# RT584ZCM33 register map
Series: ARMv8-M Mainline; File version: 1.0
CPU: CM33 r0p0, little endian, MPU, no FPU, VTOR, 3 interrupt priority bits
Registers are 32-bit, read-write, reset 0x0 unless marked. A register's access mark holds for its fields unless they carry their own. Offsets are from the block's base; [hi:lo] are bit positions.

## IRM_Non-Secure — IRM Non-Secure Register block
Base 0x40024000
Same registers: IRM_Secure 0x50024000
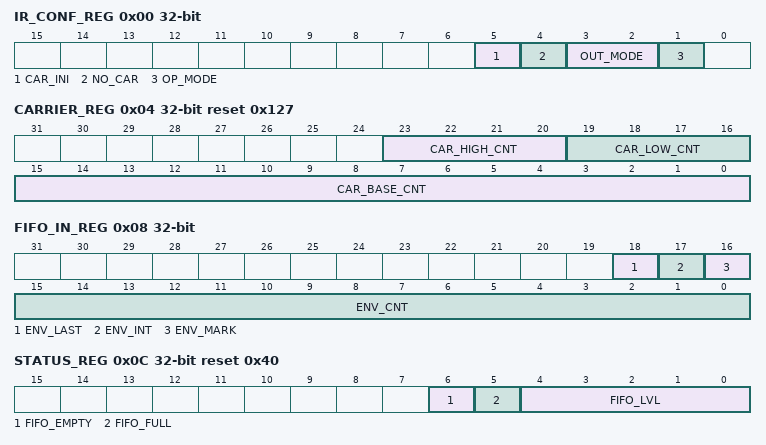
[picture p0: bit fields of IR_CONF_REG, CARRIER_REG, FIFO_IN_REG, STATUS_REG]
0x00 IR_CONF_REG — ir conf
  [5] CAR_INI — Initial Carrier Value 0: Carrier starts with '0' (the carrier is low during CAR_LOW_CNT and high during CAR_HIGH_CNT) 1: Carrier starts with '1' (the carrier is high during CAR_LOW_CNT and low during CAR_HIGH_CNT)
    0=B_5_ITEM0 (Carrier starts with '0' (the carrier is low during CAR_LOW_CNT and high during CAR_HIGH_CNT)); 1=B_5_ITEM1 (Carrier starts with '1' (the carrier is high during CAR_LOW_CNT and low during CAR_HIGH_CNT))
  [4] NO_CAR — No Carrier 0: Normal. IR Modulator output = envelope + carrier 1: Carrier is inhibited. IR Modulator output = envelope only
    0=B_4_ITEM0 (Normal. IR Modulator output = envelope + carrier); 1=B_4_ITEM1 (Carrier is inhibited. IR Modulator output = envelope only)
  [3:2] OUT_MODE — Output Logic Function 0: envelope AND carrier 1: envelope OR carrier 2: envelope NAND carrier 3: envelope NOR carrier
    0=B_2_to_3_ITEM0 (envelope AND carrier); 1=B_2_to_3_ITEM1 (envelope OR carrier); 2=B_2_to_3_ITEM2 (envelope NAND carrier); 3=B_2_to_3_ITEM3 (envelope NOR carrier)
  [1] OP_MODE — Operation mode 0: Normal Mode. IR Modulator will stop when it encounters an envelope with FIFO_IN[ENV_LAST]= 1. 1: Auto Mode. IR Modulator will transmit all envelopes and stop only when FIFO becomes empty. FIFO_IN[ENV_LAST] bit only generates an interrupt but doesn't stop.
    0=B_1_ITEM0 (Normal Mode. IR Modulator will stop when it encounters an envelope with FIFO_IN[ENV_LAST]= 1.); 1=B_1_ITEM1 (Auto Mode. IR Modulator will transmit all envelopes and stop only when FIFO becomes empty. FIFO_IN[ENV_LAST] bit only generates an interrupt but doesn't stop.)
0x04 CARRIER_REG reset 0x127 — carrier
  [23:20] CAR_HIGH_CNT — Carrier high level duration = (CAR_HIGH_CNT + 1) * CAR_BASE_CNT.
    0=B_20_to_23 (Carrier high level duration = (CAR_HIGH_CNT + 1) * CAR_BASE_CNT.)
  [19:16] CAR_LOW_CNT — Carrier low level duration = (CAR_LOW_CNT + 1) * CAR_BASE_CNT.
    0=B_16_to_19 (Carrier low level duration = (CAR_LOW_CNT + 1) * CAR_BASE_CNT.)
  [15:0] CAR_BASE_CNT — The divisor for target carrier frequency from IR source clock (32 MHz). Value 0x0 is equivalent to 0x1.
0x08 FIFO_IN_REG — fifo in
  [18] ENV_LAST wo — Last Envelope 0: IR Modulator loads the next envelope when this envelope finishes. 1: IR Modulator stops and generates an interrupt when this envelope is completely transmitted. If IR_CONF[OP_MODE] = 1, IR Modulator only generates an interrupt.
    0=B_18_ITEM0 (IR Modulator loads the next envelope when this envelope finishes.); 1=B_18_ITEM1 (IR Modulator stops and generates an interrupt when this envelope is completely transmitted. If IR_CONF[OP_MODE] = 1, IR Modulator only generates an interrupt.)
  [17] ENV_INT wo — Envelope Interrupt Generate an interrupt when starting emission of the envelope. 0: Not generate interrupt 1: Generate interrupt
    0=B_17_ITEM0 (Not generate interrupt); 1=B_17_ITEM1 (Generate interrupt)
  [16] ENV_MARK wo — Envelope Mark 0: the envelope period is a space 1: the envelope period is a mark
    0=B_16_ITEM0 (the envelope period is a space); 1=B_16_ITEM1 (the envelope period is a mark)
  [15:0] ENV_CNT wo — Envelope Duration Envelope duration expressed in carrier period number. Value 0x0000 has the same behavior as the value 0x0001.
0x0C STATUS_REG ro reset 0x40 — status
  [6] FIFO_EMPTY — IR Modulator FIFO Empty Flag 0: FIFO is not empty 1: FIFO is empty (FIFO level = 000000)
    0=B_6_ITEM0 (FIFO is not empty); 1=B_6_ITEM1 (FIFO is empty (FIFO level = 000000))
  [5] FIFO_FULL — IR Modulator FIFO Full Flag 0: FIFO is not full 1: FIFO is full (FIFO level = 100000)
    0=B_5_ITEM0 (FIFO is not full); 1=B_5_ITEM1 (FIFO is full (FIFO level = 100000))
  [4:0] FIFO_LVL — Current IR Modulator FIFO Level 0: Empty 1: 1 entry 16: 16 entries (FIFO is full)
    0=B_0_to_4 (Current IR Modulator FIFO Level 0: Empty 1: 1 entry 16: 16 entries (FIFO is full))
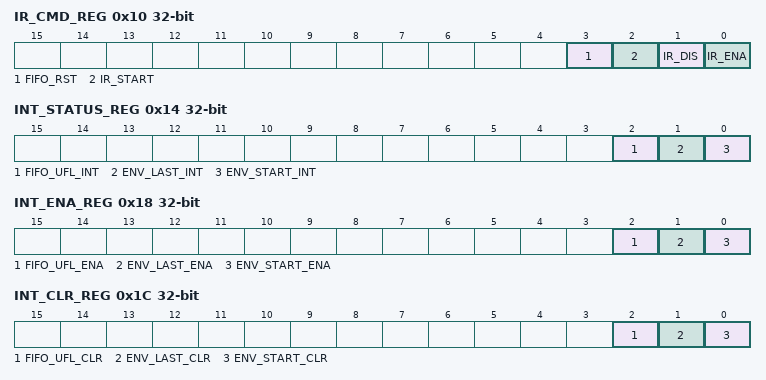
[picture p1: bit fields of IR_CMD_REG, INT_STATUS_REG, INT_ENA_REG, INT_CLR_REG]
0x10 IR_CMD_REG — ir cmd
  [3] FIFO_RST — Reset IR Modulator FIFO. This bit is self-clearing. 0: No effect 1: Reset FIFO. IR Modulator FIFO is completely re-initialized, all data in the FIFO are erased.
    0=B_3_ITEM0 (No effect); 1=B_3_ITEM1 (Reset FIFO. IR Modulator FIFO is completely re-initialized, all data in the FIFO are erased.)
  [2] IR_START — Start IR Modulator. This bit is self-clearing. 0: No effect 1: Start transmission. Before setting this field, the Modulator must be enabled (the bit field IR_ENA must be set first).
    0=B_2_ITEM0 (No effect); 1=B_2_ITEM1 (Start transmission. Before setting this field, the Modulator must be enabled (the bit field IR_ENA must be set first).)
  [1] IR_DIS — Disable IR Modulator. This bit is self-clearing. 0: No effect 1: Disable IR Modulator. The transmission of envelopes is immediately stopped. The FIFO is not reinitialized (the content of the FIFO is conserved).
    0=B_1_ITEM0 (No effect); 1=B_1_ITEM1 (Disable IR Modulator. The transmission of envelopes is immediately stopped. The FIFO is not reinitialized (the content of the FIFO is conserved).)
  [0] IR_ENA — Enable IR Modulator Unit. This bit is self-clearing. 0: No effect 1: Enable IR Modulator
    0=B_0_ITEM0 (No effect); 1=B_0_ITEM1 (Enable IR Modulator)
0x14 INT_STATUS_REG ro — int status
  [2] FIFO_UFL_INT — IR Modulator FIFO Underflow (FIFO_UFL) Interrupt This interrupt occurs when IR Modulator tries to transmit data but the FIFO is empty. 0: Interrupt is not pending 1: Interrupt is pending
    0=B_2_ITEM0 (Interrupt is not pending); 1=B_2_ITEM1 (Interrupt is pending)
  [1] ENV_LAST_INT — Envelop Last (ENV_LAST) Interrupt The interrupt occurs when IR Modulator has finished transmitting an envelope with FIFO_IN[ENV_LAST] =1. 0: Interrupt is not pending 1: Interrupt is pending
    0=B_1_ITEM0 (Interrupt is not pending); 1=B_1_ITEM1 (Interrupt is pending)
  [0] ENV_START_INT — Envelop Start (ENV_START) Interrupt This interrupt occurs when IR Modulator has started to transmit an envelope with FIFO_IN[ENV_INT] = 1 0: Interrupt is not pending 1: Interrupt is pending
    0=B_0_ITEM0 (Interrupt is not pending); 1=B_0_ITEM1 (Interrupt is pending)
0x18 INT_ENA_REG — int ena
  [2] FIFO_UFL_ENA — Enable/Disable FIFO_UFL Interrupt 0: Disable FIFO_UFL interrupt 1: Enable FIFO_UFL interrupt
    0=B_2_ITEM0 (Disable FIFO_UFL interrupt); 1=B_2_ITEM1 (Enable FIFO_UFL interrupt)
  [1] ENV_LAST_ENA — Enable/Disable ENV_LAST Interrupt 0: Disable ENV_ LAST interrupt 1: Enable ENV_ LAST interrupt
    0=B_1_ITEM0 (Disable ENV_ LAST interrupt); 1=B_1_ITEM1 (Enable ENV_ LAST interrupt)
  [0] ENV_START_ENA — Enable/Disable ENV_START Interrupt 0: Disable ENV_START interrupt 1: Enable ENV_START interrupt
    0=B_0_ITEM0 (Disable ENV_START interrupt); 1=B_0_ITEM1 (Enable ENV_START interrupt)
0x1C INT_CLR_REG — int clr
  [2] FIFO_UFL_CLR wo — Clear FIFO_UFL interrupt This bit is self-clearing. 0: No effect 1: Clear FIFO_UFL interrupt
    0=B_2_ITEM0 (No effect); 1=B_2_ITEM1 (Clear FIFO_UFL interrupt)
  [1] ENV_LAST_CLR wo — Clear ENV_LAST interrupt This bit is self-clearing. 0: No effect 1: Clear ENV_ LAST interrupt
    0=B_1_ITEM0 (No effect); 1=B_1_ITEM1 (Clear ENV_ LAST interrupt)
  [0] ENV_START_CLR wo — Clear ENV_START interrupt This bit is self-clearing. 0: No effect 1: Clear ENV_START interrupt
    0=B_0_ITEM0 (No effect); 1=B_0_ITEM1 (Clear ENV_START interrupt)
